# STM32U083xx register map
File version: 1.0
Registers are 32-bit, read-write, reset 0x0 unless marked. A register's access mark holds for its fields unless they carry their own. Offsets are from the block's base; [hi:lo] are bit positions.

## USART3 — Universal Synchronous Asynchronous Receiver Transmitter
Base 0x40004800
Same registers: USART4 0x40004C00
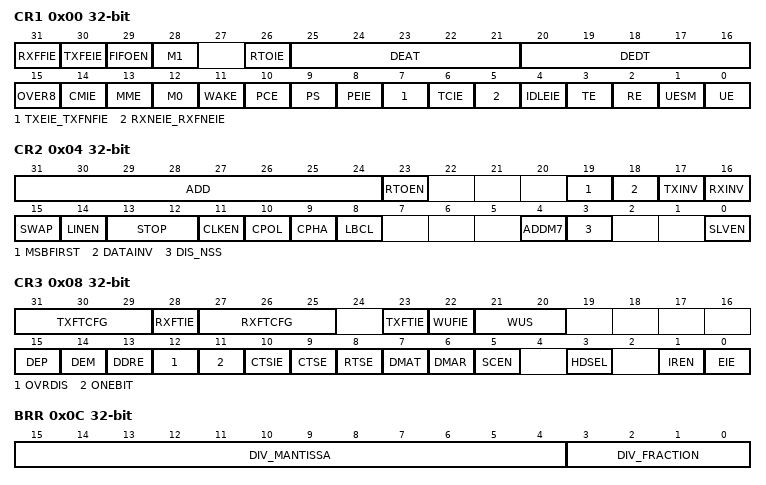
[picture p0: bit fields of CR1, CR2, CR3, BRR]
0x00 CR1 — USART Control register 1
  [31] RXFFIE — RXFIFO Full interrupt enable
  [30] TXFEIE — TXFIFO empty interrupt enable
  [29] FIFOEN — FIFO mode enable
  [28] M1 — Word length - Bit 1
  [26] RTOIE — Receive Time Out interrupt enable
  [25:21] DEAT — DEAT[4:0] bits (Driver Enable Assertion Time)
  [20:16] DEDT — DEDT[4:0] bits (Driver Enable Deassertion Time)
  [15] OVER8 — Oversampling by 8-bit or 16-bit mode
    0=OVERSAMPLING_16 (Oversampling by 16); 1=OVERSAMPLING_8 (Oversampling by 8)
  [14] CMIE — Character match interrupt enable
  [13] MME — Mute Mode Enable
  [12] M0 — Word length - Bit 0
  [11] WAKE — Receiver Wakeup method
    0=IDLELINE (LPUART wake up from Mute mode on Idle Line); 1=ADDRESSMARK (LPUART wake up from Mute mode on Address Mark)
  [10] PCE — Parity Control Enable
  [9] PS — Parity Selection
  [8] PEIE — PE Interrupt Enable
  [7] TXEIE_TXFNFIE — TXE and TX FIFO Not Full Interrupt Enable
  [6] TCIE — Transmission Complete Interrupt Enable
  [5] RXNEIE_RXFNEIE — RXNE and RX FIFO Not Empty Interrupt Enable
  [4] IDLEIE — IDLE Interrupt Enable
  [3] TE — Transmitter Enable
  [2] RE — Receiver Enable
  [1] UESM — USART Enable in STOP Mode
  [0] UE — USART Enable
0x04 CR2 — USART Control register 2
  [31:24] ADD — Address of the USART node
  [23] RTOEN — Receiver Time-Out enable
  [19] MSBFIRST — Most Significant Bit First
    0=LSBFIRST; 1=MSBFIRST
  [18] DATAINV — Binary data inversion
    0=POSITIVE; 1=NEGATIVE
  [17] TXINV — TX pin active level inversion
    0=STANDARD (TX pin signal works using the standard logic levels); 1=INVERTED (TX pin signal values are inverted.)
  [16] RXINV — RX pin active level inversion
    0=STANDARD (RX pin signal works using the standard logic levels); 1=INVERTED (RX pin signal values are inverted.)
  [15] SWAP — SWAP TX/RX pins
    0=STANDARD (TX/RX pins are used as defined in standard pinout); 1=SWAPPED (TX and RX pins functions are swapped.)
  [14] LINEN — LIN mode enable
  [13:12] STOP — STOP[1:0] bits (STOP bits)
    0=STOPBITS_1 (1 stop bit); 2=STOPBITS_2 (2 stop bits); 1=STOPBITS_0_5 (0.5 stop bit); 3=STOPBITS_1_5 (1.5 stop bits)
  [11] CLKEN — Clock Enable
  [10] CPOL — Clock Polarity
    0=LOW (Steady low value on SCLK pin outside transmission window); 1=HIGH (Steady high value on SCLK pin outside transmission window)
  [9] CPHA — Clock Phase
    0=PHASE_1EDGE (The first clock transition is the first data capture edge); 1=PHASE_2EDGE (The second clock transition is the first data capture edge)
  [8] LBCL — Last Bit Clock pulse
    0=NO_OUTPUT (The clock pulse of the last data bit is not output to the SCLK pin); 1=OUTPUT (The clock pulse of the last data bit is output to the SCLK pin)
  [4] ADDM7 — 7-bit or 4-bit Address Detection
    0=DETECT_4B (4-bit address detection method selected); 1=DETECT_7B (7-bit address detection (in 8-bit data mode) method selected)
  [3] DIS_NSS — Negative Slave Select (NSS) pin management
  [0] SLVEN — Synchronous Slave mode Enable
0x08 CR3 — USART Control register 3
  [31:29] TXFTCFG — TXFIFO [2:0] threshold configuration
  [28] RXFTIE — RXFIFO threshold interrupt enable
  [27:25] RXFTCFG — RXFTCFG [2:0]Receive FIFO threshold configuration
  [23] TXFTIE — TXFIFO threshold interrupt enable
  [22] WUFIE — Wake Up Interrupt Enable
  [21:20] WUS — WUS[1:0] bits (Wake UP Interrupt Flag Selection)
    0=ADDRESS (Wake up active on address match); 2=STARTBIT (Wake up active on Start bit detection); 3=RXNE (Wake up active on RXNE)
  [15] DEP — Driver Enable Polarity Selection
    0=HIGH (DE signal is active high); 1=LOW (DE signal is active low)
  [14] DEM — Driver Enable Mode
  [13] DDRE — DMA Disable on Reception Error
  [12] OVRDIS — Overrun Disable
  [11] ONEBIT — One sample bit method enable
  [10] CTSIE — CTS Interrupt Enable
  [9] CTSE — CTS Enable
  [8] RTSE — RTS Enable
  [7] DMAT — DMA Enable Transmitter
  [6] DMAR — DMA Enable Receiver
  [5] SCEN — SmartCard mode enable
  [3] HDSEL — Half-Duplex Selection
  [1] IREN — IrDA mode Enable
  [0] EIE — Error Interrupt Enable
0x0C BRR — USART Baud rate register
  [15:4] DIV_MANTISSA — Mantissa of USARTDIV
  [3:0] DIV_FRACTION — Fraction of USARTDIV
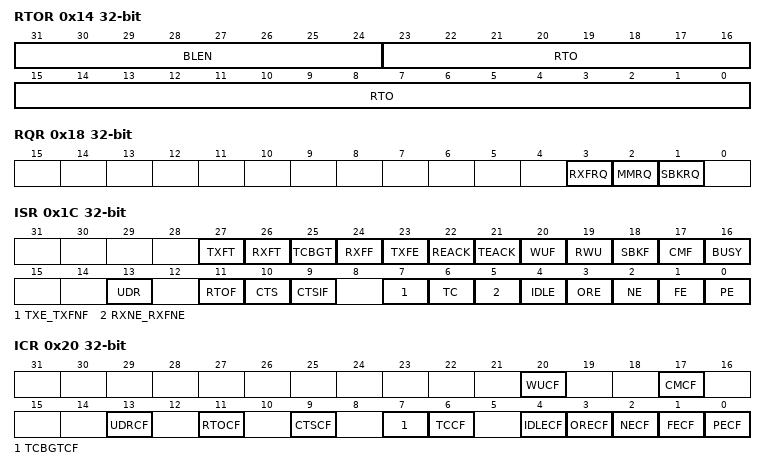
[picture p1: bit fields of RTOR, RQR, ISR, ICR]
0x14 RTOR — USART Receiver Time Out register
  [31:24] BLEN — Block Length
  [23:0] RTO — Receiver Time Out Value
0x18 RQR — USART Request register
  [3] RXFRQ — Receive Data flush Request
  [2] MMRQ — Mute Mode Request
  [1] SBKRQ — Send Break Request
0x1C ISR — USART Interrupt and status register
  [27] TXFT — TXFIFO threshold Flag
  [26] RXFT — RXFIFO threshold Flag
  [25] TCBGT — Transmission complete before guard time Flag
  [24] RXFF — RXFIFO Full Flag
  [23] TXFE — TXFIFO Empty
  [22] REACK — Receive Enable Acknowledge Flag
  [21] TEACK — Transmit Enable Acknowledge Flag
  [20] WUF — Wake Up from stop mode Flag
  [19] RWU — Receive Wake Up from mute mode Flag
  [18] SBKF — Send Break Flag
  [17] CMF — Character Match Flag
  [16] BUSY — Busy Flag
  [13] UDR — SPI slave underrun error flag
  [11] RTOF — Receiver Time Out
  [10] CTS — CTS flag
  [9] CTSIF — CTS interrupt flag
  [7] TXE_TXFNF — Transmit Data Register Empty or TX FIFO Not Full Flag
  [6] TC — Transmission Complete
  [5] RXNE_RXFNE — Read Data Register or RX FIFO Not Empty
  [4] IDLE — IDLE line detected
  [3] ORE — OverRun Error
  [2] NE — Noise detected Flag
  [1] FE — Framing Error
  [0] PE — Parity Error
0x20 ICR — USART Interrupt flag Clear register
  [20] WUCF — Wake Up from stop mode Clear Flag
  [17] CMCF — Character Match Clear Flag
  [13] UDRCF — SPI slave underrun clear flag
  [11] RTOCF — Receiver Time Out Clear Flag
  [9] CTSCF — CTS Interrupt Clear Flag
  [7] TCBGTCF — Transmission complete before guard time Clear Flag
  [6] TCCF — Transmission Complete Clear Flag
  [4] IDLECF — IDLE line detected Clear Flag
  [3] ORECF — OverRun Error Clear Flag
  [2] NECF — Noise detected Clear Flag
  [1] FECF — Framing Error Clear Flag
  [0] PECF — Parity Error Clear Flag
0x24 RDR — USART Receive Data register
  [8:0] RDR — RDR[8:0] bits (Receive Data value)
0x28 TDR — USART Transmit Data register
  [8:0] TDR — TDR[8:0] bits (Transmit Data value)
0x2C PRESC — USART clock Prescaler register
  [3:0] PRESCALER — PRESCALER[3:0] bits (Clock prescaler)
    0=DIV1 (Input clock not divided); 1=DIV2 (Input clock divided by 2); 2=DIV4 (Input clock divided by 4); 3=DIV6; 4=DIV8 (Input clock divided by 8); 5=DIV10; 6=DIV12; 7=DIV16; 8=DIV32 (Input clock divided by 32); 9=DIV64; 10=DIV128; 11=DIV256

## LPUART1 — Universal Synchronous Asynchronous Receiver Transmitter
Base 0x40008000
Same registers: LPUART2 0x40008400, LPUART3 0x40008C00
Registers as USART3; these are added or differ:
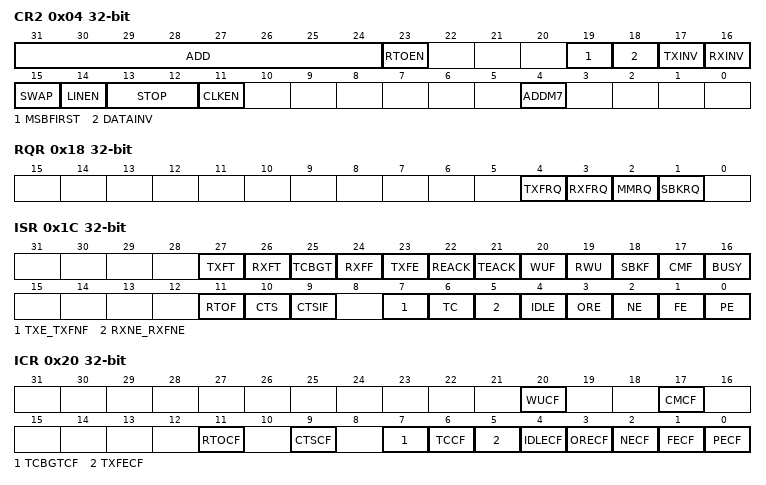
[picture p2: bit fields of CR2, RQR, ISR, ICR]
0x04 CR2 — USART Control register 2
  [31:24] ADD — Address of the USART node
  [23] RTOEN — Receiver Time-Out enable
  [19] MSBFIRST — Most Significant Bit First
    0=LSBFIRST; 1=MSBFIRST
  [18] DATAINV — Binary data inversion
    0=POSITIVE; 1=NEGATIVE
  [17] TXINV — TX pin active level inversion
    0=STANDARD (TX pin signal works using the standard logic levels); 1=INVERTED (TX pin signal values are inverted.)
  [16] RXINV — RX pin active level inversion
    0=STANDARD (RX pin signal works using the standard logic levels); 1=INVERTED (RX pin signal values are inverted.)
  [15] SWAP — SWAP TX/RX pins
    0=STANDARD (TX/RX pins are used as defined in standard pinout); 1=SWAPPED (TX and RX pins functions are swapped.)
  [14] LINEN — LIN mode enable
  [13:12] STOP — STOP[1:0] bits (STOP bits)
    0=STOPBITS_1 (1 stop bit); 2=STOPBITS_2 (2 stop bits); 1=STOPBITS_0_5 (0.5 stop bit); 3=STOPBITS_1_5 (1.5 stop bits)
  [11] CLKEN — Clock Enable
  [4] ADDM7 — 7-bit or 4-bit Address Detection
    0=DETECT_4B (4-bit address detection method selected); 1=DETECT_7B (7-bit address detection (in 8-bit data mode) method selected)
0x18 RQR — USART Request register
  [4] TXFRQ — Transmit data flush Request
  [3] RXFRQ — Receive Data flush Request
  [2] MMRQ — Mute Mode Request
  [1] SBKRQ — Send Break Request
0x1C ISR — USART Interrupt and status register
  [27] TXFT — TXFIFO threshold Flag
  [26] RXFT — RXFIFO threshold Flag
  [25] TCBGT — Transmission complete before guard time Flag
  [24] RXFF — RXFIFO Full Flag
  [23] TXFE — TXFIFO Empty
  [22] REACK — Receive Enable Acknowledge Flag
  [21] TEACK — Transmit Enable Acknowledge Flag
  [20] WUF — Wake Up from stop mode Flag
  [19] RWU — Receive Wake Up from mute mode Flag
  [18] SBKF — Send Break Flag
  [17] CMF — Character Match Flag
  [16] BUSY — Busy Flag
  [11] RTOF — Receiver Time Out
  [10] CTS — CTS flag
  [9] CTSIF — CTS interrupt flag
  [7] TXE_TXFNF — Transmit Data Register Empty or TX FIFO Not Full Flag
  [6] TC — Transmission Complete
  [5] RXNE_RXFNE — Read Data Register or RX FIFO Not Empty
  [4] IDLE — IDLE line detected
  [3] ORE — OverRun Error
  [2] NE — Noise detected Flag
  [1] FE — Framing Error
  [0] PE — Parity Error
0x20 ICR — USART Interrupt flag Clear register
  [20] WUCF — Wake Up from stop mode Clear Flag
  [17] CMCF — Character Match Clear Flag
  [11] RTOCF — Receiver Time Out Clear Flag
  [9] CTSCF — CTS Interrupt Clear Flag
  [7] TCBGTCF — Transmission complete before guard time Clear Flag
  [6] TCCF — Transmission Complete Clear Flag
  [5] TXFECF — TXFIFO empty clear flag
  [4] IDLECF — IDLE line detected Clear Flag
  [3] ORECF — OverRun Error Clear Flag
  [2] NECF — Noise detected Clear Flag
  [1] FECF — Framing Error Clear Flag
  [0] PECF — Parity Error Clear Flag
